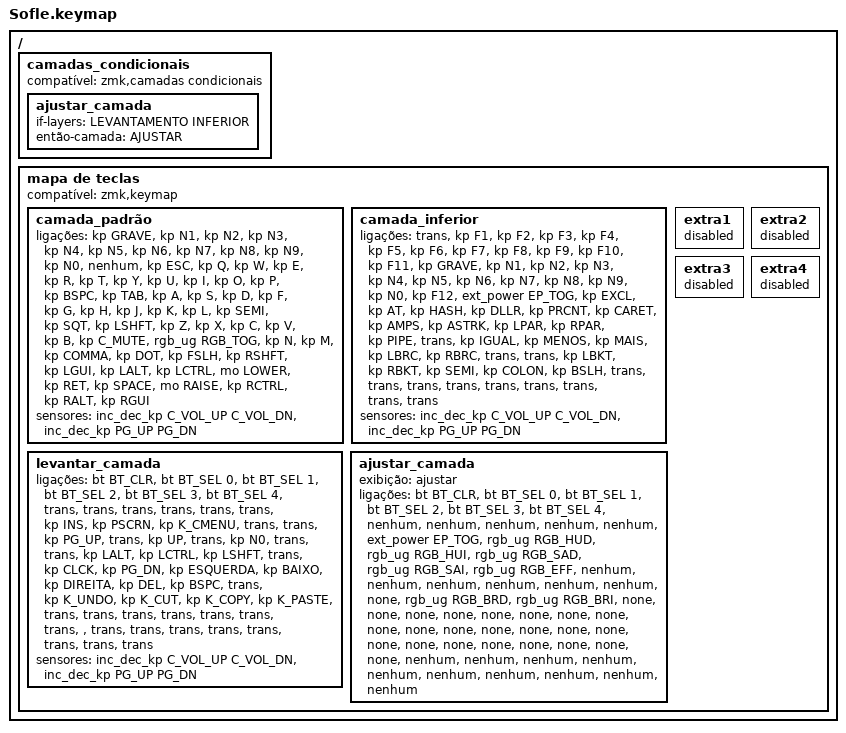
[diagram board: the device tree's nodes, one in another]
/*
 * Copyright (c) 2020 The ZMK Contributors
 *
 * SPDX-License-Identifier: MIT
 */

#include <behaviors.dtsi>
#include <dt-bindings/zmk/keys.h>
#include <dt-bindings/zmk/bt.h>
#include <dt-bindings/zmk/rgb.h>
#include <dt-bindings/zmk/ext_power.h>

#define BASE 0
#define LOWER 1
#define RAISE 2
#define ADJUST 3

/ {

 // Ative a camada AJUSTAR pressionando aumentar e diminuir
 camadas_condicionais {
 compatível = "zmk,camadas condicionais";
 ajustar_camada {
 if-layers = <LEVANTAMENTO INFERIOR>;
 então-camada = <AJUSTAR>;
 };
 };

 mapa de teclas {
 compatível = "zmk,keymap";

 camada_padrão {
// ------------------------------------------------------------------------------------------------
// | ` | 1 | 2 | 3 | 4 | 5 | | 6 | 7 | 8 | 9 | 0 | |
// | ESC | Q | W | E | R | T | | Y | U | I | O | P | BKSPC |
// | ABA | A | S | D | F | G | | H | J | K | L | ; | ' |
// | DESLOCAMENTO | Z | X | C | V | B | MUDO | | | N | M | , | . | / | MUDANÇA |
// | GUI | ALT | CTRL | LOWER| ENTER | | ESPAÇO | ELEVAR| CTRL | ALT | GUI |
 ligações = <
&kp GRAVE &kp N1 &kp N2 &kp N3 &kp N4 &kp N5 &kp N6 &kp N7 &kp N8 &kp N9 &kp N0 &nenhum
&kp ESC &kp Q &kp W &kp E &kp R &kp T &kp Y &kp U &kp I &kp O &kp P &kp BSPC
&kp TAB &kp A &kp S &kp D &kp F &kp G &kp H &kp J &kp K &kp L &kp SEMI &kp SQT
&kp LSHFT &kp Z &kp X &kp C &kp V &kp B &kp C_MUTE &rgb_ug RGB_TOG &kp N &kp M &kp COMMA &kp DOT &kp FSLH &kp RSHFT
 &kp LGUI &kp LALT &kp LCTRL &mo LOWER &kp RET &kp SPACE &mo RAISE &kp RCTRL &kp RALT &kp RGUI
 >;

 ligações de sensores = <&inc_dec_kp C_VOL_UP C_VOL_DN &inc_dec_kp PG_UP PG_DN>;
 };

 camada_inferior {
// TODO: Algumas vinculações estão aguardando suporte a código-chave deslocado.
// ------------------------------------------------------------------------------------------------
// | | F1 | F2 | F3 | F4 | F5 | | F6 | F7 | F8 | F9 | F10 | F11 |
// | ` | 1 | 2 | 3 | 4 | 5 | | 6 | 7 | 8 | 9 | 0 | F12 |
// | | ! | @ | # | $ | % | | ^ | & | * | ( | ) | | |
// | | = | - | + | { | } | | | | [ | ] | ; | : | \ | |
// | | | | | | | | | | |
 ligações = <
&trans &kp F1 &kp F2 &kp F3 &kp F4 &kp F5 &kp F6 &kp F7 &kp F8 &kp F9 &kp F10 &kp F11
&kp GRAVE &kp N1 &kp N2 &kp N3 &kp N4 &kp N5 &kp N6 &kp N7 &kp N8 &kp N9 &kp N0 &kp F12
&ext_power EP_TOG &kp EXCL &kp AT &kp HASH &kp DLLR &kp PRCNT &kp CARET &kp AMPS &kp ASTRK &kp LPAR &kp RPAR &kp PIPE
&trans &kp IGUAL &kp MENOS &kp MAIS &kp LBRC &kp RBRC &trans &trans &kp LBKT &kp RBKT &kp SEMI &kp COLON &kp BSLH &trans
 &trans &trans &trans &trans &trans &trans &trans &trans
 >;

 ligações de sensores = <&inc_dec_kp C_VOL_UP C_VOL_DN &inc_dec_kp PG_UP PG_DN>;
 };

 levantar_camada {
// ------------------------------------------------------------------------------------------------
// | BTCLR | BT1 | BT2 | BT3 | BT4 | BT5 | | | | | | | |
// | | INS | PSCR | GUI | | | | PGUP | | ^ | | | |
// | | ALT | CTRL | SHIFT | | CAPS | | PGDN | <- | v | -> | DEL | BKSPC |
// | | DESFAZER | CORTAR | COPIAR | COLAR | | | | | | | | | | |
// | | | | | | | | | | |
 ligações = <
&bt BT_CLR &bt BT_SEL 0 &bt BT_SEL 1 &bt BT_SEL 2 &bt BT_SEL 3 &bt BT_SEL 4 &trans &trans &trans &trans &trans
&trans &kp INS &kp PSCRN &kp K_CMENU &trans &trans &kp PG_UP &trans &kp UP &trans &kp N0 &trans
&trans &kp LALT &kp LCTRL &kp LSHFT &trans &kp CLCK &kp PG_DN &kp ESQUERDA &kp BAIXO &kp DIREITA &kp DEL &kp BSPC
&trans &kp K_UNDO &kp K_CUT &kp K_COPY &kp K_PASTE &trans &trans &trans &trans &trans &trans &trans &
 &trans &trans &trans &trans &trans &trans &trans &trans
 >;

 ligações de sensores = <&inc_dec_kp C_VOL_UP C_VOL_DN &inc_dec_kp PG_UP PG_DN>;
 };

 ajustar_camada {
// ----------------------------------------------------------------------------------------------------------------
// | BTCLR | BT1 | BT2 | BT3 | BT4 | BT5 | | | | | | | |
// | EXTPWR | RGB_HUD | RGB_HUI | RGB_SAD | RGB_SAI | RGB_EFF | | | | | | | |
// | | RGB_BRD | RGB_BRI | | | | | | | | | |
// | | | | | | | RGB_TOG | | | | | | | | |
// | | | | | | | | | | |
 nome de exibição = "ajustar";
 ligações = <
&bt BT_CLR &bt BT_SEL 0 &bt BT_SEL 1 &bt BT_SEL 2 &bt BT_SEL 3 &bt BT_SEL 4 &nenhum &nenhum &nenhum &nenhum &nenhum
&ext_power EP_TOG &rgb_ug RGB_HUD &rgb_ug RGB_HUI &rgb_ug RGB_SAD &rgb_ug RGB_SAI &rgb_ug RGB_EFF &nenhum &nenhum &nenhum &nenhum &nenhum &nenhum
&none &rgb_ug RGB_BRD &rgb_ug RGB_BRI &none &none &none &none &none &none &none &none &none
&none &none &none &none &none &none &none &none &none &none &none &none &none &none
 &nenhum &nenhum &nenhum &nenhum &nenhum &nenhum &nenhum &nenhum &nenhum &nenhum
 >;
 };
 extra1 {
 status = "reservado";
 };
 extra2 {
 status = "reservado";
 };
 extra3 {
 status = "reservado";
 };
 extra4 {
 status = "reservado";
 };

 };
};
